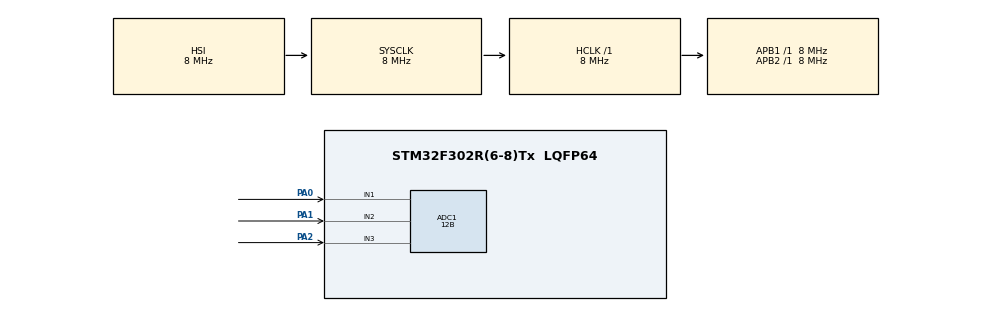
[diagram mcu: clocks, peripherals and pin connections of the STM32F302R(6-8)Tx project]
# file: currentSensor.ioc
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ADC1.Channel-0\#ChannelRegularConversion=ADC_CHANNEL_1
ADC1.Channel-1\#ChannelRegularConversion=ADC_CHANNEL_2
ADC1.Channel-2\#ChannelRegularConversion=ADC_CHANNEL_3
ADC1.ClockPrescaler=ADC_CLOCK_SYNC_PCLK_DIV4
ADC1.ContinuousConvMode=ENABLE
ADC1.DMAContinuousRequests=ENABLE
ADC1.DataAlign=ADC_DATAALIGN_RIGHT
ADC1.DiscontinuousConvMode=DISABLE
ADC1.EOCSelection=ADC_EOC_SEQ_CONV
ADC1.EnableAnalogWatchDog1=false
ADC1.EnableAnalogWatchDog2=false
ADC1.EnableAnalogWatchDog3=false
ADC1.EnableInjectedConversion=ENABLE
ADC1.EnableRegularConversion=ENABLE
ADC1.ExternalTrigConv=ADC_EXTERNALTRIGCONV_T2_TRGO
ADC1.ExternalTrigConvEdge=ADC_EXTERNALTRIGCONVEDGE_RISING
ADC1.InjNumberOfConversion=0
ADC1.LowPowerAutoWait=DISABLE
ADC1.NbrOfConversion=3
ADC1.NbrOfConversionFlag=1
ADC1.Offset-0\#ChannelRegularConversion=0
ADC1.Offset-1\#ChannelRegularConversion=0
ADC1.Offset-2\#ChannelRegularConversion=0
ADC1.OffsetNumber-0\#ChannelRegularConversion=ADC_OFFSET_NONE
ADC1.OffsetNumber-1\#ChannelRegularConversion=ADC_OFFSET_NONE
ADC1.OffsetNumber-2\#ChannelRegularConversion=ADC_OFFSET_NONE
ADC1.Overrun=ADC_OVR_DATA_OVERWRITTEN
ADC1.Rank-0\#ChannelRegularConversion=1
ADC1.Rank-1\#ChannelRegularConversion=2
ADC1.Rank-2\#ChannelRegularConversion=3
ADC1.Resolution=ADC_RESOLUTION_12B
ADC1.SamplingTime-0\#ChannelRegularConversion=ADC_SAMPLETIME_19CYCLES_5
ADC1.SamplingTime-1\#ChannelRegularConversion=ADC_SAMPLETIME_19CYCLES_5
ADC1.SamplingTime-2\#ChannelRegularConversion=ADC_SAMPLETIME_19CYCLES_5
ADC1.ScanConvMode=ADC_SCAN_ENABLE
ADC1.SubFamily=STM32F302x8
ADC1.master=1
Dma.ADC1.0.Direction=DMA_PERIPH_TO_MEMORY
Dma.ADC1.0.Instance=DMA1_Channel1
Dma.ADC1.0.MemDataAlignment=DMA_MDATAALIGN_WORD
Dma.ADC1.0.MemInc=DMA_MINC_ENABLE
Dma.ADC1.0.Mode=DMA_CIRCULAR
Dma.ADC1.0.PeriphDataAlignment=DMA_PDATAALIGN_WORD
Dma.ADC1.0.PeriphInc=DMA_PINC_DISABLE
Dma.ADC1.0.Priority=DMA_PRIORITY_LOW
Dma.Request0=ADC1
Mcu.Family=STM32F3
Mcu.Name=STM32F302R(6-8)Tx
Mcu.Package=LQFP64
NVIC.DMA1_Channel1_IRQn=true\:0\:0\:false\:false\:true\:false
NVIC.PriorityGroup=NVIC_PRIORITYGROUP_4
PA0.Mode=IN1-Single-Ended
PA0.Signal=ADC1_IN1
PA1.Mode=IN2-Single-Ended
PA1.Signal=ADC1_IN2
PA2.Mode=IN3-Single-Ended
PA2.Signal=ADC1_IN3
ProjectManager.HeapSize=0x200
ProjectManager.StackSize=0x400
ProjectManager.TargetToolchain=MDK-ARM V5
RCC.AHBFreq_Value=8000000
RCC.APB1Freq_Value=8000000
RCC.APB2Freq_Value=8000000
RCC.CortexFreq_Value=8000000
RCC.HSE_VALUE=8000000
RCC.HSI_VALUE=8000000
RCC.LSE_VALUE=32768
RCC.PLLMUL=RCC_PLL_MUL4
RCC.SYSCLKFreq_VALUE=8000000
RCC.USBFreq_Value=16000000
TIM2.Period=100
TIM2.Prescaler=800
TIM2.TIM_MasterOutputTrigger=TIM_TRGO_UPDATE
VP_TIM2_VS_ClockSourceINT.Mode=Internal
board=custom

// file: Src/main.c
/**
  ******************************************************************************
  * @file           : main.c
  * @brief          : Main program body
  ******************************************************************************
  ** This notice applies to any and all portions of this file
  * that are not between comment pairs USER CODE BEGIN and
  * USER CODE END. Other portions of this file, whether
  * inserted by the user or by software development tools
  * are owned by their respective copyright owners.
  *
  * COPYRIGHT(c) 2018 STMicroelectronics
  *
  * Redistribution and use in source and binary forms, with or without modification,
  * are permitted provided that the following conditions are met:
  *   1. Redistributions of source code must retain the above copyright notice,
  *      this list of conditions and the following disclaimer.
  *   2. Redistributions in binary form must reproduce the above copyright notice,
  *      this list of conditions and the following disclaimer in the documentation
  *      and/or other materials provided with the distribution.
  *   3. Neither the name of STMicroelectronics nor the names of its contributors
  *      may be used to endorse or promote products derived from this software
  *      without specific prior written permission.
  *
  * THIS SOFTWARE IS PROVIDED BY THE COPYRIGHT HOLDERS AND CONTRIBUTORS "AS IS"
  * AND ANY EXPRESS OR IMPLIED WARRANTIES, INCLUDING, BUT NOT LIMITED TO, THE
  * IMPLIED WARRANTIES OF MERCHANTABILITY AND FITNESS FOR A PARTICULAR PURPOSE ARE
  * DISCLAIMED. IN NO EVENT SHALL THE COPYRIGHT HOLDER OR CONTRIBUTORS BE LIABLE
  * FOR ANY DIRECT, INDIRECT, INCIDENTAL, SPECIAL, EXEMPLARY, OR CONSEQUENTIAL
  * DAMAGES (INCLUDING, BUT NOT LIMITED TO, PROCUREMENT OF SUBSTITUTE GOODS OR
  * SERVICES; LOSS OF USE, DATA, OR PROFITS; OR BUSINESS INTERRUPTION) HOWEVER
  * CAUSED AND ON ANY THEORY OF LIABILITY, WHETHER IN CONTRACT, STRICT LIABILITY,
  * OR TORT (INCLUDING NEGLIGENCE OR OTHERWISE) ARISING IN ANY WAY OUT OF THE USE
  * OF THIS SOFTWARE, EVEN IF ADVISED OF THE POSSIBILITY OF SUCH DAMAGE.
  *
  ******************************************************************************
  */
#include "main.h"
#include "stm32f3xx_hal.h"

ADC_HandleTypeDef hadc1;
DMA_HandleTypeDef hdma_adc1;

TIM_HandleTypeDef htim2;

/* USER CODE BEGIN PV */
/* Private variables ---------------------------------------------------------*/
uint32_t ADC_BUF[3];
/* USER CODE END PV */

void SystemClock_Config(void);
static void MX_GPIO_Init(void);
static void MX_DMA_Init(void);
static void MX_ADC1_Init(void);
static void MX_TIM2_Init(void);

/* USER CODE BEGIN PFP */
/* Private function prototypes -----------------------------------------------*/

/* USER CODE END PFP */

int main(void)
{

  /* MCU Configuration----------------------------------------------------------*/

  /* Reset of all peripherals, Initializes the Flash interface and the Systick. */
  HAL_Init();

  /* Configure the system clock */
  SystemClock_Config();

  /* Initialize all configured peripherals */
  MX_GPIO_Init();
  MX_DMA_Init();
  MX_ADC1_Init();
  MX_TIM2_Init();
  /* USER CODE BEGIN 2 */

	//start time
	HAL_TIM_Base_Start(&htim2);

 //start adc as dma
	HAL_ADC_Start_DMA(&hadc1, ADC_BUF, 3);
	//HAL_ADC_Start_IT(&hadc1);

  /* USER CODE END 2 */

  /* Infinite loop */
  while (1)
  {

  }

}

void SystemClock_Config(void)
{

  RCC_OscInitTypeDef RCC_OscInitStruct;
  RCC_ClkInitTypeDef RCC_ClkInitStruct;

    /**Initializes the CPU, AHB and APB busses clocks
    */
  RCC_OscInitStruct.OscillatorType = RCC_OSCILLATORTYPE_HSI;
  RCC_OscInitStruct.HSIState = RCC_HSI_ON;
  RCC_OscInitStruct.HSICalibrationValue = 16;
  RCC_OscInitStruct.PLL.PLLState = RCC_PLL_NONE;
  if (HAL_RCC_OscConfig(&RCC_OscInitStruct) != HAL_OK)
  {
    _Error_Handler(__FILE__, __LINE__);
  }

    /**Initializes the CPU, AHB and APB busses clocks
    */
  RCC_ClkInitStruct.ClockType = RCC_CLOCKTYPE_HCLK|RCC_CLOCKTYPE_SYSCLK
                              |RCC_CLOCKTYPE_PCLK1|RCC_CLOCKTYPE_PCLK2;
  RCC_ClkInitStruct.SYSCLKSource = RCC_SYSCLKSOURCE_HSI;
  RCC_ClkInitStruct.AHBCLKDivider = RCC_SYSCLK_DIV1;
  RCC_ClkInitStruct.APB1CLKDivider = RCC_HCLK_DIV1;
  RCC_ClkInitStruct.APB2CLKDivider = RCC_HCLK_DIV1;

  if (HAL_RCC_ClockConfig(&RCC_ClkInitStruct, FLASH_LATENCY_0) != HAL_OK)
  {
    _Error_Handler(__FILE__, __LINE__);
  }

    /**Configure the Systick interrupt time
    */
  HAL_SYSTICK_Config(HAL_RCC_GetHCLKFreq()/1000);

    /**Configure the Systick
    */
  HAL_SYSTICK_CLKSourceConfig(SYSTICK_CLKSOURCE_HCLK);

  /* SysTick_IRQn interrupt configuration */
  HAL_NVIC_SetPriority(SysTick_IRQn, 0, 0);
}

/* ADC1 init function */
static void MX_ADC1_Init(void)
{

  ADC_ChannelConfTypeDef sConfig;

    /**Common config
    */
  hadc1.Instance = ADC1;
  hadc1.Init.ClockPrescaler = ADC_CLOCK_SYNC_PCLK_DIV4;
  hadc1.Init.Resolution = ADC_RESOLUTION_12B;
  hadc1.Init.ScanConvMode = ADC_SCAN_ENABLE;
  hadc1.Init.ContinuousConvMode = ENABLE;
  hadc1.Init.DiscontinuousConvMode = DISABLE;
  hadc1.Init.ExternalTrigConvEdge = ADC_EXTERNALTRIGCONVEDGE_RISING;
  hadc1.Init.ExternalTrigConv = ADC_EXTERNALTRIGCONV_T2_TRGO;
  hadc1.Init.DataAlign = ADC_DATAALIGN_RIGHT;
  hadc1.Init.NbrOfConversion = 3;
  hadc1.Init.DMAContinuousRequests = ENABLE;
  hadc1.Init.EOCSelection = ADC_EOC_SINGLE_CONV;
  hadc1.Init.LowPowerAutoWait = DISABLE;
  hadc1.Init.Overrun = ADC_OVR_DATA_OVERWRITTEN;
  if (HAL_ADC_Init(&hadc1) != HAL_OK)
  {
    _Error_Handler(__FILE__, __LINE__);
  }

    /**Configure Regular Channel
    */
  sConfig.Channel = ADC_CHANNEL_1;
  sConfig.Rank = ADC_REGULAR_RANK_1;
  sConfig.SingleDiff = ADC_SINGLE_ENDED;
  sConfig.SamplingTime = ADC_SAMPLETIME_19CYCLES_5;
  sConfig.OffsetNumber = ADC_OFFSET_NONE;
  sConfig.Offset = 0;
  if (HAL_ADC_ConfigChannel(&hadc1, &sConfig) != HAL_OK)
  {
    _Error_Handler(__FILE__, __LINE__);
  }

    /**Configure Regular Channel
    */
  sConfig.Channel = ADC_CHANNEL_2;
  sConfig.Rank = ADC_REGULAR_RANK_2;
  if (HAL_ADC_ConfigChannel(&hadc1, &sConfig) != HAL_OK)
  {
    _Error_Handler(__FILE__, __LINE__);
  }

    /**Configure Regular Channel
    */
  sConfig.Channel = ADC_CHANNEL_3;
  sConfig.Rank = ADC_REGULAR_RANK_3;
  if (HAL_ADC_ConfigChannel(&hadc1, &sConfig) != HAL_OK)
  {
    _Error_Handler(__FILE__, __LINE__);
  }

}

/* TIM2 init function */
static void MX_TIM2_Init(void)
{

  TIM_ClockConfigTypeDef sClockSourceConfig;
  TIM_MasterConfigTypeDef sMasterConfig;

  htim2.Instance = TIM2;
  htim2.Init.Prescaler = 800;
  htim2.Init.CounterMode = TIM_COUNTERMODE_UP;
  htim2.Init.Period = 100;
  htim2.Init.ClockDivision = TIM_CLOCKDIVISION_DIV1;
  htim2.Init.AutoReloadPreload = TIM_AUTORELOAD_PRELOAD_DISABLE;
  if (HAL_TIM_Base_Init(&htim2) != HAL_OK)
  {
    _Error_Handler(__FILE__, __LINE__);
  }

  sClockSourceConfig.ClockSource = TIM_CLOCKSOURCE_INTERNAL;
  if (HAL_TIM_ConfigClockSource(&htim2, &sClockSourceConfig) != HAL_OK)
  {
    _Error_Handler(__FILE__, __LINE__);
  }

  sMasterConfig.MasterOutputTrigger = TIM_TRGO_UPDATE;
  sMasterConfig.MasterSlaveMode = TIM_MASTERSLAVEMODE_DISABLE;
  if (HAL_TIMEx_MasterConfigSynchronization(&htim2, &sMasterConfig) != HAL_OK)
  {
    _Error_Handler(__FILE__, __LINE__);
  }

}

static void MX_DMA_Init(void)
{
  /* DMA controller clock enable */
  __HAL_RCC_DMA1_CLK_ENABLE();

  /* DMA interrupt init */
  /* DMA1_Channel1_IRQn interrupt configuration */
  HAL_NVIC_SetPriority(DMA1_Channel1_IRQn, 0, 0);
  HAL_NVIC_EnableIRQ(DMA1_Channel1_IRQn);

}

/** Pinout Configuration
*/
static void MX_GPIO_Init(void)
{

  /* GPIO Ports Clock Enable */
  __HAL_RCC_GPIOA_CLK_ENABLE();

}

void _Error_Handler(char *file, int line)
{
  while(1)
  {
  }
}

/************************ (C) COPYRIGHT STMicroelectronics *****END OF FILE****/
